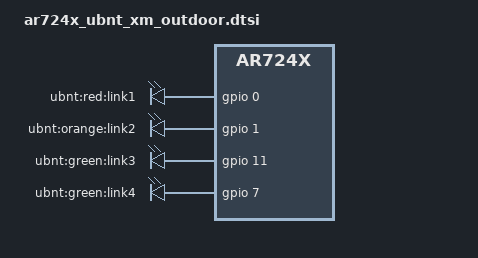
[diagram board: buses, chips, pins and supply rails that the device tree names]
// SPDX-License-Identifier: GPL-2.0-or-later OR MIT

/ {
	aliases {
		led-boot = &led_link4;
		led-failsafe = &led_link4;
		label-mac-device = &wifi;
	};

	leds {
		compatible = "gpio-leds";

		link1 {
			label = "ubnt:red:link1";
			gpios = <&gpio 0 GPIO_ACTIVE_HIGH>;
		};

		link2 {
			label = "ubnt:orange:link2";
			gpios = <&gpio 1 GPIO_ACTIVE_HIGH>;
		};

		link3 {
			label = "ubnt:green:link3";
			gpios = <&gpio 11 GPIO_ACTIVE_HIGH>;
		};

		led_link4: link4 {
			label = "ubnt:green:link4";
			gpios = <&gpio 7 GPIO_ACTIVE_HIGH>;
		};
	};
};
